# f29h85x_ssu_gen_regs register map
Vendor: Texas Instruments
Peripheral module from a debugger description file (folder C29).
Registers are 32-bit, read-write, no defined reset value unless marked. A register's access mark holds for its fields unless they carry their own. Offsets are as the file gives them; lines under a group give offsets from that group; [hi:lo] are bit positions; {n}, {i} and the like mark numbered series; 'fields as' and 'values as' point back to an identical list; <NAME> marks a mode.

## SSU_GEN_REGS — SSU GEN Registers
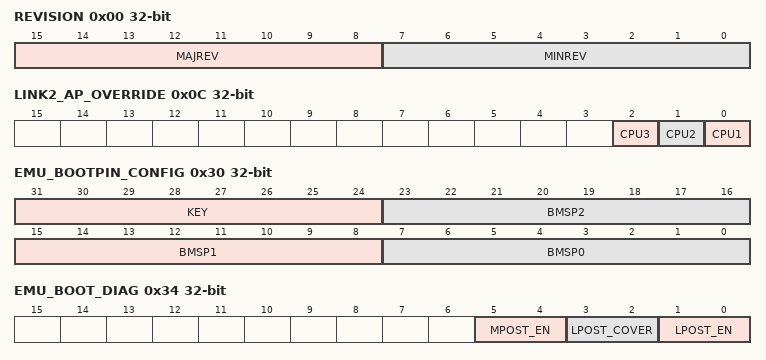
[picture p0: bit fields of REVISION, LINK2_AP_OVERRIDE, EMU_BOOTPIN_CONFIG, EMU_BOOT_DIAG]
0x00 REVISION ro — Module Revision Register
  [15:8] MAJREV — Major Revision Number
  [7:0] MINREV — Minor Revision Number
0x04 UPP_REVISION — User Protection Policy Revision
  [15:0] REV
0x08 SSUMODE — Safety and Security Operational Mode
  [5:0] OPMODE — SSU Operational Mode
0x0C LINK2_AP_OVERRIDE — LINK2 Access Protection Override Register
  [2] CPU3 — CPU3 LINK2 Access Protection Override Bit
  [1] CPU2 — CPU2 LINK2 Access Protection Override Bit
  [0] CPU1 — CPU1 LINK2 Access Protection Override Bit
0x2C BOOTMODE_STAT — User Boot Mode Status Register
  [2:0] PIN_STAT — Boot Mode Pin Status
0x30 EMU_BOOTPIN_CONFIG — User Emulation Boot Pin Configuration
  [31:24] KEY — Register Valid Key
  [23:16] BMSP2 — Boot Mode Select Pin 2
  [15:8] BMSP1 — Boot Mode Select Pin 1
  [7:0] BMSP0 — Boot Mode Select Pin 0
0x34 EMU_BOOT_DIAG — User Emulation Boot Options
  [5:4] MPOST_EN — MPOST Enable
  [3:2] LPOST_COVER — LPOST Coverage
  [1:0] LPOST_EN — LPOST Enable
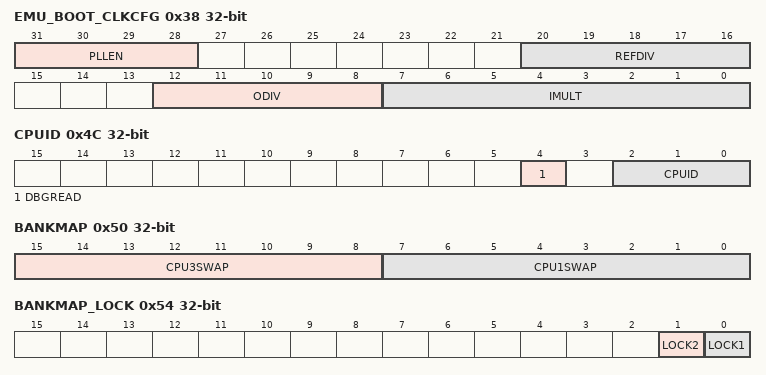
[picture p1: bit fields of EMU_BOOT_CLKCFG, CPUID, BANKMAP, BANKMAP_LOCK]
0x38 EMU_BOOT_CLKCFG — User Emulation Boot Clock Configuration Register
  [31:28] PLLEN — Secure Boot PLL Enable
  [20:16] REFDIV — Secure Boot PLL REFDIV
  [12:8] ODIV — Secure Boot PLL ODIV
  [7:0] IMULT — Secure Boot PLL IMULT
0x3C EMU_BOOTEN — User Emulation Boot Enable
  [0] ENABLE — Emulation Boot Enable
0x40 RAMOPEN_LOCK — RAMOPEN Feature Lock Register
  [7:0] LOCK — RAMOPEN Lock
0x44 RAMOPEN_COMMIT — RAMOPEN Feature Commit Register
  [0] COMMIT — Permanent Commit
0x4C CPUID ro
  [4] DBGREAD — Debug Read Status
  [2:0] CPUID — CPUID Value
0x50 BANKMAP — Valid Banks
  [15:8] CPU3SWAP — CPU3 Bank Swap
  [7:0] CPU1SWAP — CPU1 Bank Swap
0x54 BANKMAP_LOCK
  [1] LOCK2 — CPU3 Bank Swap Lock
  [0] LOCK1 — CPU1 Bank Swap Lock
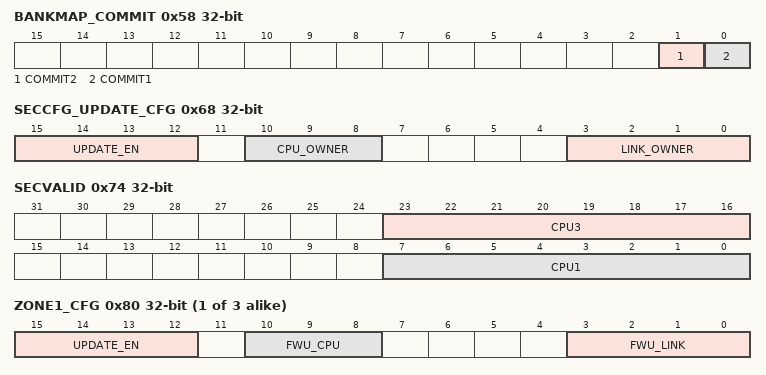
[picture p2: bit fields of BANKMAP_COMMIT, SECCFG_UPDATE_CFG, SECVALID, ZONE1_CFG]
0x58 BANKMAP_COMMIT
  [1] COMMIT2 — CPU3 Bank Swap Commit
  [0] COMMIT1 — CPU1 Bank Swap Commit
0x5C BANKMODE — Bank Mode Configuration Register
  [3:0] MODE — Device Flash Configuration Mode
0x60 BANKMODE_LOCK
  [0] LOCK — Bank Mode Lock
0x64 BANKMODE_COMMIT
  [0] COMMIT — Bank Mode Commit
0x68 SECCFG_UPDATE_CFG — SECCFG Flash Update Configuration Register
  [15:12] UPDATE_EN — SECCFG Update Enable
  [10:8] CPU_OWNER — SECCFG Update Owner CPU
  [3:0] LINK_OWNER — SECCFG Update Owner LINK
0x70 PROG_BANKMODE — Programming BANKMODE Register
  [1:0] MODE — Device Flash Configuration Mode
0x74 SECVALID — Valid SECCFG Sector
  [23:16] CPU3 — Valid CPU3 SECCFG Sector
  [7:0] CPU1 — Valid CPU1/CPU2 SECCFG Sector
0x78 SECVALID_LOCK — Valid SECCFG Sector Lock Register
  [0] LOCK — SECVALID LOCK
0x7C SECVALID_COMMIT — Valid SECCFG Sector Commit Register
  [0] COMMIT — Security Sectors Commit
{0x7C+4i} ZONE{i}_CFG (i=1..3) — ZONE{i} Configuration
  [15:12] UPDATE_EN — ZONE{i} Update Enable
  [10:8] FWU_CPU — Firmware Update Owner CPU
  [3:0] FWU_LINK — Firmware Update Owner LINK
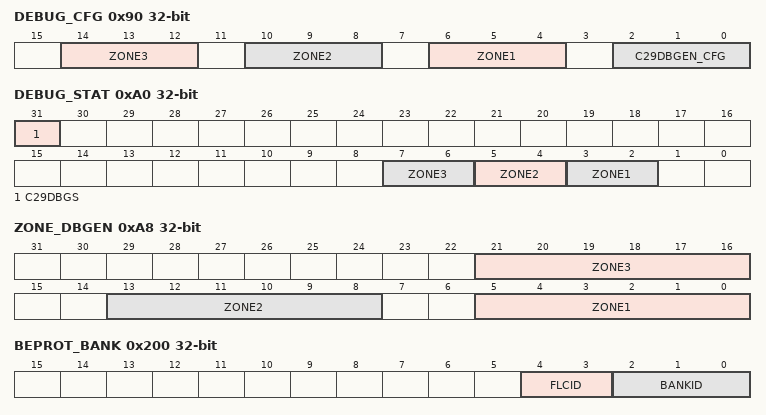
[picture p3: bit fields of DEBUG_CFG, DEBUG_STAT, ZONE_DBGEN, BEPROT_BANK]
0x90 DEBUG_CFG — Debug Configuration
  [14:12] ZONE3 — ZONE3 Debug Enable Configuration
  [10:8] ZONE2 — ZONE2 Debug Enable Configuration
  [6:4] ZONE1 — ZONE1 Debug Enable Configuration
  [2:0] C29DBGEN_CFG — C29DBGEN Enable Configuration
0x94 DEBUG_CFG_LOCK — Debug Configuration Lock Register
  [0] LOCK — Temporary Lock
0x98 DEBUG_CFG_COMMIT — Debug Configuration Commit Register
  [0] COMMIT — Permanent Commit
0xA0 DEBUG_STAT ro — Debug Status Register
  [31] C29DBGS — C29 Debug Status
  [7:6] ZONE3 — ZONE3 Debug State
  [5:4] ZONE2 — ZONE2 Debug State
  [3:2] ZONE1 — ZONE1 Debug State
0xA4 C29DBGEN — C29 Debug Enable Register
  [3:0] ENA — C29 Debug Enable
0xA8 ZONE_DBGEN — ZONE Debug Enable Register
  [21:16] ZONE3 — ZONE3 Debug Enable
  [13:8] ZONE2 — ZONE2 Debug Enable
  [5:0] ZONE1 — ZONE1 Debug Enable
0x200 BEPROT_BANK — Bank Erase Protection Bank Register
  [4:3] FLCID — Bank Erase Bank
  [2:0] BANKID — Bank Erase Bank
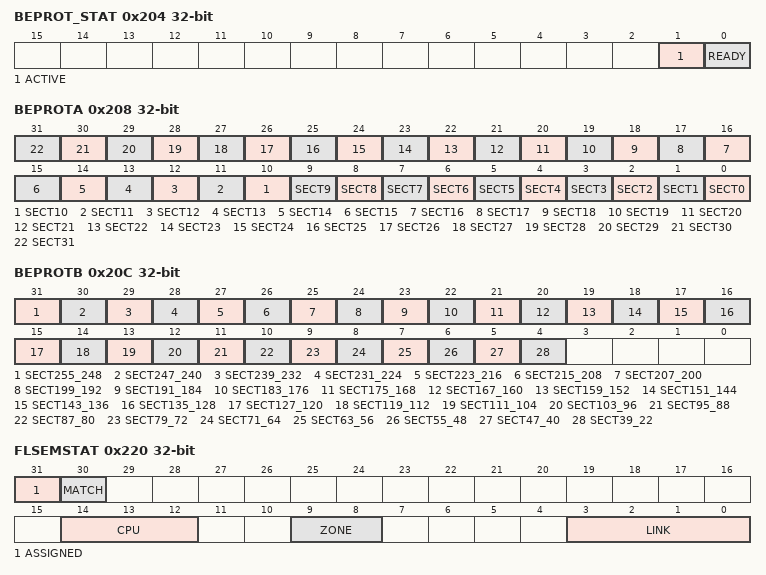
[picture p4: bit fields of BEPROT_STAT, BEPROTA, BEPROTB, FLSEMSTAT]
0x204 BEPROT_STAT ro — Bank Erase Status Register
  [1] ACTIVE — Bank Erase State Machine Initializing
  [0] READY — Bank Erase State Machine Ready
0x208 BEPROTA ro — Bank Erase Protection Register A
  [n] SECT{n} (n=0..31) — Sector {n} Bank Erase Protection
0x20C BEPROTB ro — Bank Erase Protection Register B
  [31] SECT255_248 — Sectors 255 - 248 Bank Erase Protection
  [30] SECT247_240 — Sectors 247 - 240 Bank Erase Protection
  [29] SECT239_232 — Sectors 239 - 232 Bank Erase Protection
  [28] SECT231_224 — Sectors 231 - 224 Bank Erase Protection
  [27] SECT223_216 — Sectors 223 - 216 Bank Erase Protection
  [26] SECT215_208 — Sectors 215 - 208 Bank Erase Protection
  [25] SECT207_200 — Sectors 207 - 200 Bank Erase Protection
  [24] SECT199_192 — Sectors 199 - 192 Bank Erase Protection
  [23] SECT191_184 — Sectors 191 - 184 Bank Erase Protection
  [22] SECT183_176 — Sectors 183 - 176 Bank Erase Protection
  [21] SECT175_168 — Sectors 175 - 168 Bank Erase Protection
  [20] SECT167_160 — Sectors 167 - 160 Bank Erase Protection
  [19] SECT159_152 — Sectors 159 - 152 Bank Erase Protection
  [18] SECT151_144 — Sectors 151 - 144 Bank Erase Protection
  [17] SECT143_136 — Sectors 143 - 136 Bank Erase Protection
  [16] SECT135_128 — Sectors 135 - 128 Bank Erase Protection
  [15] SECT127_120 — Sectors 127 - 120 Bank Erase Protection
  [14] SECT119_112 — Sectors 119 - 112 Bank Erase Protection
  [13] SECT111_104 — Sectors 111 - 104 Bank Erase Protection
  [12] SECT103_96 — Sectors 103 - 96 Bank Erase Protection
  [11] SECT95_88 — Sectors 95 - 88 Bank Erase Protection
  [10] SECT87_80 — Sectors 87 - 80 Bank Erase Protection
  [9] SECT79_72 — Sectors 79 - 72 Bank Erase Protection
  [8] SECT71_64 — Sectors 71 - 64 Bank Erase Protection
  [7] SECT63_56 — Sectors 63 - 56 Bank Erase Protection
  [6] SECT55_48 — Sectors 55 - 48 Bank Erase Protection
  [5] SECT47_40 — Sectors 47 - 40 Bank Erase Protection
  [4] SECT39_22 — Sectors 39 - 22 Bank Erase Protection
0x220 FLSEMSTAT ro — Flash Controller Semaphore Status Register
  [31] ASSIGNED — Assigned Flag
  [30] MATCH — Match Status Bit
  [14:12] CPU — Semaphore CPU Owner
  [9:8] ZONE — Semaphore ZONE Owner
  [3:0] LINK — Semaphore LINK Owner
0x224 FLSEMREQ — Flash Controller Semaphore Request Register
  [0] REQ — Request Semaphore Ownership
0x228 FLSEMCLR — Flash Controller Semaphore Clear Register
  [0] CLR — Release Semaphore Ownership
0x230 WEPROT_CODE_BANKS — Global Code Banks Write Erase
  [0] PROT — Global Code Banks WEPROT
0x234 WEPROT_CODE_BANKS_LOCK — Global Code Banks Write Erase Lock
  [0] LOCK — System Access Protection Register Lock
0x238 WEPROT_CODE_BANKS_COMMIT — Global Code Banks Write Erase Commit
  [0] COMMIT — System Access Protection Register Commit
0x240 WEPROT_DATA_BANKS — Global Data Banks Write Erase
  [0] PROT — Global Data Banks WEPROT
0x244 WEPROT_DATA_BANKS_LOCK — Global Data Banks Write Erase Lock
  [0] LOCK — System Access Protection Register Lock
0x248 WEPROT_DATA_BANKS_COMMIT — Global Data Banks Write Erase Commit
  [0] COMMIT — System Access Protection Register Commit
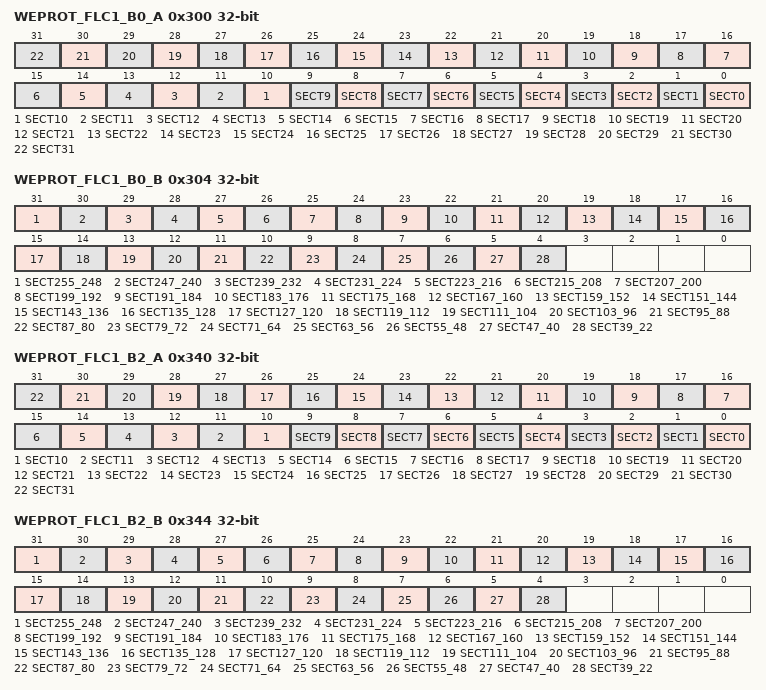
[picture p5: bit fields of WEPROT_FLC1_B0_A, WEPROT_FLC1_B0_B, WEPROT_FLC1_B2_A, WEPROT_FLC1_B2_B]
0x300 WEPROT_FLC1_B0_A — Flash Controller 1 B0 Write Erase Protection A
  [n] SECT{n} (n=0..31) — Sector {n} Write Erase Protection
0x304 WEPROT_FLC1_B0_B — Flash Controller 1 B0 Write Erase Protection B
  [31] SECT255_248 — Sectors 255 - 248 Write Erase Protection
  [30] SECT247_240 — Sectors 247 - 240 Write Erase Protection
  [29] SECT239_232 — Sectors 239 - 232 Write Erase Protection
  [28] SECT231_224 — Sectors 231 - 224 Write Erase Protection
  [27] SECT223_216 — Sectors 223 - 216 Write Erase Protection
  [26] SECT215_208 — Sectors 215 - 208 Write Erase Protection
  [25] SECT207_200 — Sectors 207 - 200 Write Erase Protection
  [24] SECT199_192 — Sectors 199 - 192 Write Erase Protection
  [23] SECT191_184 — Sectors 191 - 184 Write Erase Protection
  [22] SECT183_176 — Sectors 183 - 176 Write Erase Protection
  [21] SECT175_168 — Sectors 175 - 168 Write Erase Protection
  [20] SECT167_160 — Sectors 167 - 160 Write Erase Protection
  [19] SECT159_152 — Sectors 159 - 152 Write Erase Protection
  [18] SECT151_144 — Sectors 151 - 144 Write Erase Protection
  [17] SECT143_136 — Sectors 143 - 136 Write Erase Protection
  [16] SECT135_128 — Sectors 135 - 128 Write Erase Protection
  [15] SECT127_120 — Sectors 127 - 120 Write Erase Protection
  [14] SECT119_112 — Sectors 119 - 112 Write Erase Protection
  [13] SECT111_104 — Sectors 111 - 104 Write Erase Protection
  [12] SECT103_96 — Sectors 103 - 96 Write Erase Protection
  [11] SECT95_88 — Sectors 95 - 88 Write Erase Protection
  [10] SECT87_80 — Sectors 87 - 80 Write Erase Protection
  [9] SECT79_72 — Sectors 79 - 72 Write Erase Protection
  [8] SECT71_64 — Sectors 71 - 64 Write Erase Protection
  [7] SECT63_56 — Sectors 63 - 56 Write Erase Protection
  [6] SECT55_48 — Sectors 55 - 48 Write Erase Protection
  [5] SECT47_40 — Sectors 47 - 40 Write Erase Protection
  [4] SECT39_22 — Sectors 39 - 22 Write Erase Protection
0x310 WEPROT_FLC1_B0_LOCK — Flash Controller 1 B0 WEPROTA Lock
  [0] LOCK — System Access Protection Register Lock
0x314 WEPROT_FLC1_B0_COMMIT — Flash Controller 1 B0 WEPROTA Commit
  [0] COMMIT — System Access Protection Register Commit
0x340 WEPROT_FLC1_B2_A — Flash Controller 1 B2 Write Erase Protection A
  [n] SECT{n} (n=0..31) — Sector {n} Write Erase Protection
0x344 WEPROT_FLC1_B2_B — Flash Controller 1 B2 Write Erase Protection B
  fields as WEPROT_FLC1_B0_B
0x350 WEPROT_FLC1_B2_LOCK — Flash Controller 1 B2 WEPROTA Lock
  [0] LOCK — System Access Protection Register Lock
0x354 WEPROT_FLC1_B2_COMMIT — Flash Controller 1 B2 WEPROTA Commit
  [0] COMMIT — System Access Protection Register Commit
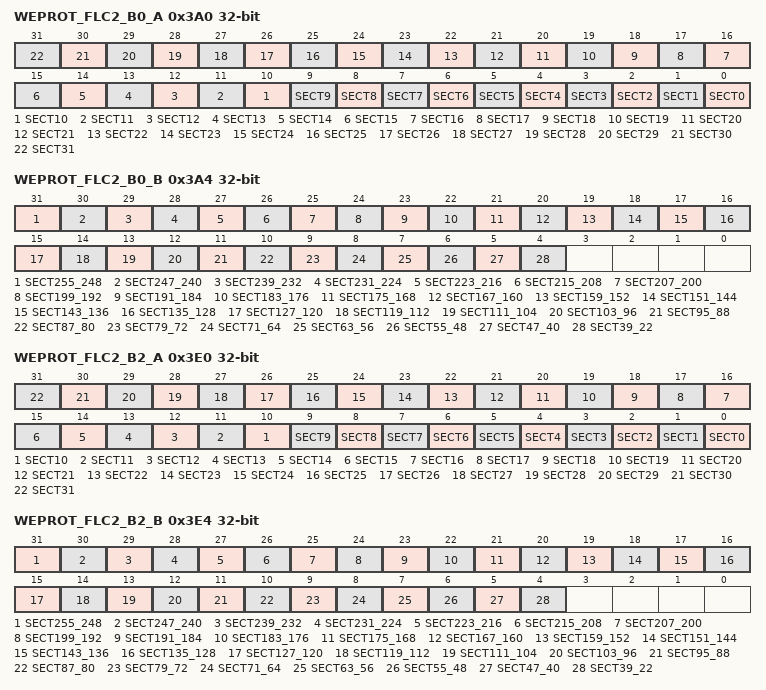
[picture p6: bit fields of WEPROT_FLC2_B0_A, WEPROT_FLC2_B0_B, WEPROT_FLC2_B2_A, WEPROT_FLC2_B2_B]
0x3A0 WEPROT_FLC2_B0_A — Flash Controller 2 B0 Write Erase Protection A
  [n] SECT{n} (n=0..31) — Sector {n} Write Erase Protection
0x3A4 WEPROT_FLC2_B0_B — Flash Controller 2 B0 Write Erase Protection B
  fields as WEPROT_FLC1_B0_B
0x3B0 WEPROT_FLC2_B0_LOCK — Flash Controller 2 B0 WEPROTA Lock
  [0] LOCK — System Access Protection Register Lock
0x3B4 WEPROT_FLC2_B0_COMMIT — Flash Controller 2 B0 WEPROTA Commit
  [0] COMMIT — System Access Protection Register Commit
0x3E0 WEPROT_FLC2_B2_A — Flash Controller 2 B2 Write Erase Protection A
  [n] SECT{n} (n=0..31) — Sector {n} Write Erase Protection
0x3E4 WEPROT_FLC2_B2_B — Flash Controller 2 B2 Write Erase Protection B
  fields as WEPROT_FLC1_B0_B
0x3F0 WEPROT_FLC2_B2_LOCK — Flash Controller 2 B2 WEPROTA Lock
  [0] LOCK — System Access Protection Register Lock
0x3F4 WEPROT_FLC2_B2_COMMIT — Flash Controller 2 B2 WEPROTA Commit
  [0] COMMIT — System Access Protection Register Commit
